# RTI0 register map
Vendor: Texas Instruments
Peripheral module from a debugger description file (folder am65x).
Registers are 32-bit, read-write, reset 0x0 unless marked. A register's access mark holds for its fields unless they carry their own. Offsets are as the file gives them; lines under a group give offsets from that group; [hi:lo] are bit positions; {n}, {i} and the like mark numbered series; 'fields as' and 'values as' point back to an identical list; <NAME> marks a mode.

## RTI0
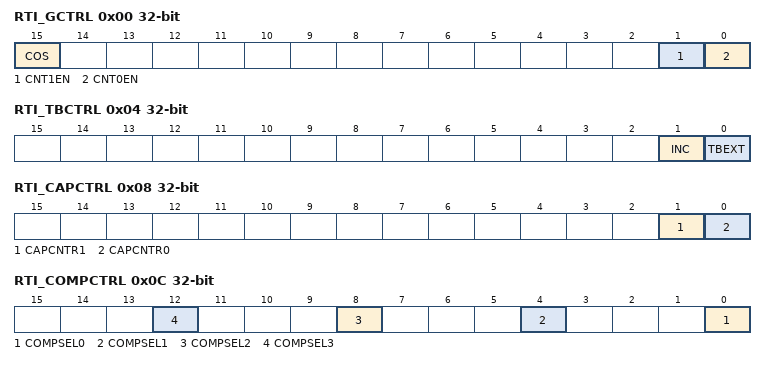
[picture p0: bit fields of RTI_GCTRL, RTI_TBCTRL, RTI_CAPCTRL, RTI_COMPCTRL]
0x00 RTI_GCTRL access per field
  [15] COS rw — Continue On Suspend. This bit determines if both counters are stopped when the device goes into debug mode or if they continue counting. User and privilege mode (read): 0 = counters are stopped while in debug mode 1 = counters are running while in debug mode Privilege mode (write): 0 = stop counters in debug mode 1 = continue counting in debug mode
  [1] CNT1EN rw — Counter 1 Enable. The CNT1EN bit starts and stops the operation of counter block1 (UC1 and FRC1). User and privilege mode (read): 0 = counters are stopped 1 = counters are running Privilege mode (write): 0 = stop counters 1 = start counters
  [0] CNT0EN rw — Counter 0 Enable. The CNT0EN bit starts and stops the operation of counter block0 (UC0 and FRC0). User and privilege mode (read): 0 = counters are stopped 1 = counters are running Privilege mode (write): 0 = stop counters 1 = start counters
0x04 RTI_TBCTRL access per field
  [1] INC rw — This bit determines whether the Free Running Counter 0 is automatically incremented if a failing clock on the NTUx signal is detected. User and privilege mode (read): 0 = FRC0 will not be incremented 1 = FRC0 will be incremented Privilege mode (write): 0 = Do not increment FRC0 on failing external clock 1 = Increment FRC0 on failing external clock
  [0] TBEXT rw — The Timebase External bit selects whether the Free Running Counter 0 is clocked by the internal Up Counter 0 or from the external signal NTUx. Since setting the TBEXT bit to 1 resets Up Counter 0, Free Running Counter 0 will not be incremented in this occurence. The only source which is able to increment Free Running Counter 0 is NTUx. When the Timebase Supervisor circuit detects a missing clockedge, then the TBEXT bit is reset. The selection if the external signal should be used, can only be done by software. User and privilege mode (read): 0 = UC0 clocks FRC0 1 = NTUx clocks FRC0 Privilege mode (write): 0 = MUX is switched to internal UC0 clocking scheme 1 = MUX is switched to external NTUx clocking scheme
0x08 RTI_CAPCTRL access per field
  [1] CAPCNTR1 rw — Capture Counter 0.
  [0] CAPCNTR0 rw — Capture Counter 0. This bit determines, which external interrupt source triggers a capture event of both UC0 and FRC0. User and privilege mode (read): 0 = capture event is triggered by Capture Event Source 0 1 = capture event is triggered by Capture Event Source 1 Privilege mode (write): 0 = enable capture event triggered by Capture Event Source 0 1 = enable capture event triggered by Capture Event Source 1
0x0C RTI_COMPCTRL access per field
  [4n] COMPSEL{n} rw (n=0..3) — Compare Select {n}. This bit determines the counter with which the compare value hold in compare register {n} is compared. User and privilege mode (read): 0 = value will be compared with FRC 0 1 = value will be compared with FRC 1 Privilege mode (write): 0 = enable compare with FRC 0 1 = enable compare with FRC 1
0x10 RTI_FRC0 — This registers holds the current value of the Free Running Counter 0 and will be updated continuously.
  [31:0] FRC0 — Free Running Counter 0. User and privilege mode (read): current value of the counter Privilege mode (write): The counter can be preset by writing to this register. The counter increments then from this written value upwards. Presetting counters, If counters have to be preset, they have to be stopped from counting in the
0x14 RTI_UC0
  [31:0] UC0 — Up Counter 0. User and privilege mode (read): value of the counter when the Free Running Counter 0 was read Privilege mode (write): the counter can be preset by writing to this register. The counter increments then from this written value upwards. Presetting counters: If counters have to be preset, they have to be stopped from counting in the
0x18 RTI_CPUC0
  [31:0] CPUC0 — Compare Up Counter 0. ARRAY(0x1f04380) ARRAY(0x1f04410) User and privilege mode (read): current compare value Privilege mode (write when TBEXT = 0): the compare value is updated Privilege mode (write when TBEXT = 1): the compare value is not changed
0x20 RTI_CAFRC0 ro
  [31:0] CAFRC0 — Capture Free Running Counter 0. User and privilege mode (read): value of Free Running Counter 0 on a capture event
0x24 RTI_CAUC0 ro
  [31:0] CAUC0 — Capture Up Counter 0. User and privilege mode (read): value of Up Counter 0 on a capture event
0x30 RTI_FRC1
  [31:0] FRC1 — Free Running Counter 1. User and privilege mode (read): current value of the counter Privilege mode (write): the counter can be preset by writing to this register. The counter increments then from this written value upwards. If counters have to be preset, they have to be stopped from counting in the
0x34 RTI_UC1
  [31:0] UC1 — Up Counter 1. User and privilege mode (read): value of the counter when the Free Running Counter 1 was read Privilege mode (write): the counter can be preset by writing to this register. The counter increments then from this written value upwards. Presetting counters: If counters have to be preset, they have to be disabled in the
0x38 RTI_CPUC1
  [31:0] CPUC1 — Compare Up Counter 1. ARRAY(0x1f1c750) ARRAY(0x1f1c7e0) User and privilege mode (read): current compare value Privilege mode (write): the compare value is updated
0x40 RTI_CAFRC1 ro
  [31:0] CAFRC1 — Capture Free Running Counter 1. User and privilege mode (read): value of Free Running Counter 1 on a capture event
0x44 RTI_CAUC1 ro
  [31:0] CAUC1 — Capture Up Counter 1. User and privilege mode (read): value of Up Counter 1 on a capture event
{0x50+8i} RTI_COMP{i} (i=0..3)
  [31:0] COMP{i} — Compare {i}. User and privilege mode (read): current compare value Privilege mode (write): update of the compare register with a new compare value Reset behavior: A reset does not generate a compare match, since the compare logic will only be active, when the associated counter block is enabled.
0x54 RTI_UDCP0
  [31:0] UDCP0 — Update Compare 0 Register. User and privilege mode (read): value to be added to the compare 0 register on the next compare match Privilege mode (write): new update value
0x5C RTI_UDCP1
  [31:0] UDCP1 — Update Compare 1 Register. User and privilege mode (read): value to be added to the compare 1 register on the next compare match Privilege mode (write): new update value
0x64 RTI_UDCP2 — This registers holds a value, which is added to the value in the compare 2 register each time a compare matches. This gives the possibility to generate periodic interrupts without software intervention.
  [31:0] UDCP2 — Update Compare 2 Register. User and privilege mode (read): value to be added to the compare 2 register on the next compare match Privilege mode (write): new update value
0x6C RTI_UDCP3
  [31:0] UDCP3 — Update Compare 3 Register. User and privilege mode (read): value to be added to the compare 3 register on the next compare match Privilege mode (write): new update value
0x70 RTI_TBLCOMP
  fields as RTI_UDCP3
0x74 RTI_TBHCOMP
  [31:0] TBHCOMP — This value determines when the edge detection circuit will stop monitoring the NTUx signal. It will be compared with Up Counter 0.
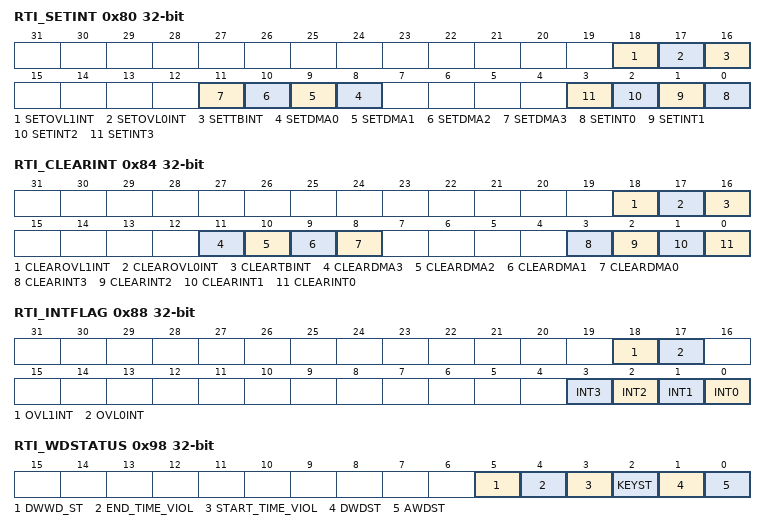
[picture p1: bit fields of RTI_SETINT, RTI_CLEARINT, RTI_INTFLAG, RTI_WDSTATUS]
0x80 RTI_SETINT access per field — This register prevents the necessity of a read-modify-write operation if a particular interrupt should be enabled. Some of the RTI features described in this section may not be supported on this family of devices. For more information, see , RTI Not Supported Features.
  [18] SETOVL1INT rw — Set Free Running Counter 1 Overflow Interrupt. User and privilege mode (read): 0 = interrupt is disabled 1 = interrupt is enabled Privilege mode (write): 0 = leaves the corresponding bit unchanged 1 = enable interrupt
  [17] SETOVL0INT rw — Set Free Running Counter 0 Overflow Interrupt. User and privilege mode (read): 0 = interrupt is disabled 1 = interrupt is enabled Privilege mode (write): 0 = leaves the corresponding bit unchanged 1 = enable interrupt
  [16] SETTBINT rw — User and privilege mode (read): 0 = interrupt is disabled 1 = interrupt is enabled Privilege mode (write): 0 = leaves the corresponding bit unchanged 1 = enable interrupt
  [n+8] SETDMA{n} rw (n=0..3) — Set Compare DMA Request {n}. User and privilege mode (read): 0 = DMA request is disabled 1 = DMA request is enabled Privilege mode (write): 0 = leaves the corresponding bit unchanged 1 = enable DMA request
  [n] SETINT{n} rw (n=0..3) — Set Compare Interrupt {n}. User and privilege mode (read): 0 = interrupt is disabled 1 = interrupt is enabled Privilege mode (write): 0 = leaves the corresponding bit unchanged 1 = enable interrupt
0x84 RTI_CLEARINT access per field — This register prevents the necessity of a read-modify-write operation if a particular interrupt should be disabled. Some of the RTI features described in this section may not be supported on this family of devices. For more information, see , RTI Not Supported Features.
  [18] CLEAROVL1INT rw — Clear Free Running Counter 1 Overflow Interrupt. User and privilege mode (read): 0 = interrupt is disabled 1 = interrupt is enabled Privilege mode (write): 0 = leaves the corresponding bit unchanged 1 = disable interrupt
  [17] CLEAROVL0INT rw — Clear Free Running Counter 0 Overflow Interrupt. User and privilege mode (read): 0 = interrupt is disabled 1 = interrupt is enabled Privilege mode (write): 0 = leaves the corresponding bit unchanged 1 = disable interrupt
  [16] CLEARTBINT rw — User and privilege mode (read): 0 = interrupt is disabled 1 = interrupt is enabled Privilege mode (write): 0 = leaves the corresponding bit unchanged 1 = disable interrupt
  [11] CLEARDMA3 rw — Clear Compare DMA Request 3. User and privilege mode (read): 0 = DMA request is disabled 1 = DMA request is enabled Privilege mode (write): 0 = leaves the corresponding bit unchanged 1 = disable DMA request
  [10] CLEARDMA2 rw — Clear Compare DMA Request 2. User and privilege mode (read): 0 = DMA request is disabled 1 = DMA request is enabled Privilege mode (write): 0 = leaves the corresponding bit unchanged 1 = disable DMA request
  [9] CLEARDMA1 rw — Clear Compare DMA Request 1. User and privilege mode (read): 0 = DMA request is disabled 1 = DMA request is enabled Privilege mode (write): 0 = leaves the corresponding bit unchanged 1 = disable DMA request
  [8] CLEARDMA0 rw — Clear Compare DMA Request 0.
  [3] CLEARINT3 rw — Clear Compare Interrupt 3. User and privilege mode (read): 0 = interrupt is disabled 1 = interrupt is enabled Privilege mode (write): 0 = leaves the corresponding bit unchanged 1 = disable interrupt
  [2] CLEARINT2 rw — Clear Compare Interrupt 2. User and privilege mode (read): 0 = interrupt is disabled 1 = interrupt is enabled Privilege mode (write): 0 = leaves the corresponding bit unchanged 1 = disable interrupt
  [1] CLEARINT1 rw — Clear Compare Interrupt 1.
  [0] CLEARINT0 rw — Clear Compare Interrupt 0. User and privilege mode (read): 0 = interrupt is disabled 1 = interrupt is enabled Privilege mode (write): 0 = leaves the corresponding bit unchanged 1 = disable interrupt
0x88 RTI_INTFLAG ro — The corresponding flags are set at every compare match of Free Running Counterx and RTICOMPx value, regardless if the interrupt is enabled or not.
  [18] OVL1INT — Free Running Counter 1 Overflow Interrupt Flag. User and privilege mode (read): determines if an interrupt is pending 0 = no interrupt pending 1 = interrupt pending Privilege mode (write): 0 = leaves the bit unchanged 1 = set the bit to 0
  [17] OVL0INT — Free Running Counter 0 Overflow Interrupt Flag. User and privilege mode (read): determines if an interrupt is pending 0 = no interrupt pending 1 = interrupt pending Privilege mode (write): 0 = leaves the bit unchanged 1 = set the bit to 0
  [n] INT{n} (n=0..3) — Interrupt Flag {n}. User and privilege mode (read): determines if an interrupt is pending 0 = no interrupt pending 1 = interrupt pending Privilege mode (write): 0 = leaves the bit unchanged 1 = set the bit to 0
0x90 RTI_DWDCTRL reset 0x5312ACED — Some of the RTI features described in this section may not be supported on this family of devices. For more information, see , RTI Not Supported Features. This register's functionality is dependent on whether the DWD is implemented to be always enabled or not. If the DWD is always enabled, then the DWD is automatically enabled after system reset is released and cannot be disabled by software. In that case, this register is redundant and any writes to this register have no effect on the DWD functionality. If, however, the DWD is not enabled upon release of system reset, then the software has to write to the DWDCTRL field in order to enable the DWD, as described below. Once enabled, the watchdog can only be disabled by a system reset. The application cannot disable the watchdog. The register also implements a one-time-write constraint. That is, once the application writes to this register to enable the watchdog, all further writes are ignored.
  [31:0] DWDCTRL — Digital Watchdog Control. User and privilege mode (read): 5312ACEDh = DWD counter is disabled. This is the default value. A98559DAh = DWD counter is enabled Any other value = DWD counter state is unchanged (enabled or disabled) Privilege mode (write): A98559DAh = DWD counter is enabled Any other value = State of DWD counter is unchanged (stays enabled or disabled) One-Write Functionality of DWDCTRL Register: The
0x94 RTI_DWDPRLD access per field reset 0xFFF — Some of the RTI features described in this section may not be supported on this family of devices. For more information, see , RTI Not Supported Features.
  [11:0] DWDPRLD rw — Digital Watchdog Preload Value. User and privilege mode (read): A read from this register in any CPU mode returns the current preload value. Privilege mode (write): If the DWD is always enabled after reset is released: The DWD starts counting down from the reset value of the counter, that is, 0x002DFFFF. The application can configure the DWD preload register any time before this down counter expires. When the application services the DWD, the preload register contents are copied left-justified into the DWD down counter and it starts counting down from that value. If the DWD is implemented such that the down counter is enabled by software: The DWD preload register can be configured only when the DWD is disabled. Therefore, the application can only configure the DWD preload register before it enables the DWD down counter. The expiration time of the DWD Down Counter can be determined with following equation: ARRAY(0x1F75D70) where:
0x98 RTI_WDSTATUS ro — Some of the RTI features described in this section may not be supported on this family of devices. For more information, see , RTI Not Supported Features. The values of the following status bits will not be affected by a system reset. These bits are cleared by a power up reset, or by the application.
  [5] DWWD_ST — Windowed Watchdog Status. This bit denotes whether the time-window defined by the windowed watchdog configuration has been violated, or if a wrong key or key sequence was written to service the watchdog. User and privilege mode (read): 0 = no time-window violation has occurred. 1 = a time-window violation has occurred. The watchdog will generate either a system reset or a non-maskable interrupt to the CPU in this case. Privilege mode (write): 0 = leaves the current value unchanged. 1 = clears the bit to 0. This will also clear all other status flags in the
  [4] END_TIME_VIOL — Windowed Watchdog End Time Violation Status. This bit denotes whether the end-time defined by the windowed watchdog configuration has been violated. This bit is effectively a copy of the DWD ST status flag. User and priviledge mode (read): 0 = no end-time window violation has occurred. 1 = the end-time defined by the windowed watchdog configuration has been violated. Priviledge mode (write): 0 = leaves the current value unchanged. 1 = clears the bit to 0.
  [3] START_TIME_VIOL — Windowed Watchdog End Time Violation Status. This bit denotes whether the start-time defined by the windowed watchdog configuration has been violated. This indicates that the WWD was serviced before the service window was opened. User and priviledge mode (read): 0 = no start-time window violation has occurred. 1 = the start-time defined by the windowed watchdog configuration has been violated. Priviledge mode (write): 0 = leaves the current value unchanged. 1 = clears the bit to 0.
  [2] KEYST — Watchdog KeyStatus.
  [1] DWDST — Digital Watchdog Status.
  [0] AWDST — Analog Watchdog Status.
0x9C RTI_WDKEY access per field reset 0xA35C — Some of the RTI features described in this section may not be supported on this family of devices. For more information, see , RTI Not Supported Features.
  [15:0] WDKEY rw — Watchdog Key. User and privilege mode reads are indeterminate. Privilege mode (write): A write of 0xE51A followed by 0xA35C in two separate write operations defines the Key Sequence and discharges the watchdog capacitor. This also causes the upper 12 bits of the DWD down counter to be reloaded with the contents of the DWD preload register and the lower 13 bits to become all 1 s. Writing any other value causes a digital watchdog reset. Register write access time precaution: The user has to take into account that the write to the register takes 3 RTI_ICLK cycle. This needs to be considered for the AWD/DWD expiration calculation. Step 1:
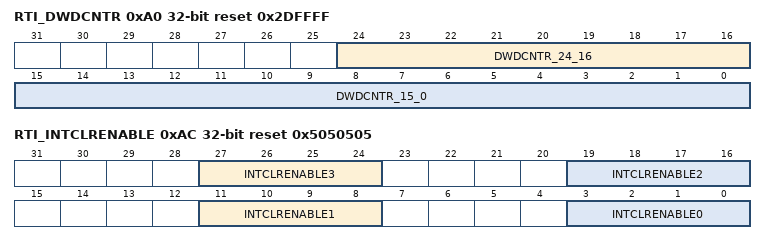
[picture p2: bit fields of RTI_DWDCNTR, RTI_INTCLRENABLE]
0xA0 RTI_DWDCNTR ro reset 0x2DFFFF — Some of the RTI features described in this section may not be supported on this family of devices. For more information, see , RTI Not Supported Features.
  [24:16] DWDCNTR_24_16 — Digital Watchdog Down Counter. The value of the DWDCNTR after a system reset is 0x002DFFFF. When the DWD is enabled and the DWD counter starts counting down from this value with an RTI_FCLK time base of 3MHz, a watchdog reset will be generated in 1 second. User and privilege mode (read): Reads return the current counter value. Privilege mode (write): Writes don t have an effect.
  [15:0] DWDCNTR_15_0 — Digital Watchdog Down Counter. The value of the DWDCNTR after a system reset is 0x002DFFFF. When the DWD is enabled and the DWD counter starts counting down from this value with an RTI_FCLK time base of 3MHz, a watchdog reset will be generated in 1 second. User and privilege mode (read): Reads return the current counter value. Privilege mode (write): Writes don t have an effect.
0xA4 RTI_WWDRXNCTRL access per field reset 0x5
  [3:0] WWDRXN rw — Digital Windowed Watchdog Reaction. User and privilege mode (read), privileged mode (write): 0x5 = This is the default value. The windowed watchdog will cause a reset if the watchdog is serviced outside the time window defined by the configuration, or if the watchdog is not serviced at all. 0xA = The windowed watchdog will generate a non-maskable interrupt to the CPU if the watchdog is serviced outside the time window defined by the configuration, or if the watchdog is not serviced at all. Writing any other value will cause a system reset if the watchdog is serviced outside the time window defined by the configuration, or if the watchdog is not serviced at all. Configuration of DWWD Reaction: The DWWD reaction can be selected by the application even when the DWWD counter is already enabled. If a change to the WWDRXN is made before the watchdog service window is opened, then the change in the configuration takes effect immediately. If a change to the WWDRXN is made when the watchdog service window is already open, then the change in configuration takes effect only after the watchdog is serviced.
0xA8 RTI_WWDSIZECTRL 16-bit reset 0x5
  [15:0] WWDSIZE — Same as below. Digital Windowed Watchdog Window Size. User and privilege mode (read), privileged mode (write): Value written to WWDSIZE: 0x00000005 = 100% Window Size (The functionality is the same as the standard time-out digital watchdog.) Value written to WWDSIZE: 0x00000050 = 50% Window Size Value written to WWDSIZE: 0x00000500 = 25% Window Size Value written to WWDSIZE: 0x00005000 = 12.5% Window Size Value written to WWDSIZE: 0x00050000 = 6.25% Window Size Value written to WWDSIZE: 0x00500000 = 3.125% Window Size Value written to WWDSIZE: Any other value = 3.125% Window Size Incorrect value being written to watchdog window size control register: If an incorrect value is written to the WWDSIZE field, or if a system disturbance causes the WWDSIZE field to have a value other than 0x5, 0x50, 0x500, 0x5000, 0x50000, or 0x500000, then the window size will be configured to be 3.125%. This increases the chances of getting a reset due to the windowed watchdog, which enables the system to handle the cause for the incorrect configuration. Configuration of DWWD Window Size: The DWWD window size can be selected by the application even when the DWWD counter is already enabled. If a change to the WWDSIZE is made before the watchdog service window is opened, then the change in the configuration takes effect immediately. If a change to the WWDSIZE is made when the watchdog service window is already open, then the change in configuration takes effect only after the watchdog is serviced.
0xAC RTI_INTCLRENABLE access per field reset 0x5050505
  [27:24] INTCLRENABLE3 rw — Enables the auto-clear functionality on the compare 3 interrupt. User and Privileged mode (read): 0x5 = Auto-clear for compare 3 interrupt is disabled. Any other value = Auto-clear for compare 3 interrupt is enabled. Privileged mode (write): 0x5 = Disables the auto-clear functionality on the compare 3 interrupt. Any other value = Enables the auto-clear functionality on the compare 3 interrupt.
  [19:16] INTCLRENABLE2 rw — Enables the auto-clear functionality on the compare 2 interrupt. User and Privileged mode (read): 0x5 = Auto-clear for compare 2 interrupt is disabled. Any other value = Auto-clear for compare 2 interrupt is enabled. Privileged mode (write): 0x5 = Disables the auto-clear functionality on the compare 2 interrupt. Any other value = Enables the auto-clear functionality on the compare 2 interrupt.
  [11:8] INTCLRENABLE1 rw — Enables the auto-clear functionality on the compare 1 interrupt. User and Privileged mode (read): 0x5 = Auto-clear for compare 1 interrupt is disabled. Any other value = Auto-clear for compare 1 interrupt is enabled. Privileged mode (write): 0x5 = Disables the auto-clear functionality on the compare 1 interrupt. Any other value = Enables the auto-clear functionality on the compare 1 interrupt.
  [3:0] INTCLRENABLE0 rw — Enables the auto-clear functionality on the compare 0 interrupt. User and Privileged mode (read): 0x5 = Auto-clear for compare 0 interrupt is disabled. Any other value = Auto-clear for compare 0 interrupt is enabled. Privileged mode (write): 0x5 = Disables the auto-clear functionality on the compare 0 interrupt. Any other value = Enables the auto-clear functionality on the compare 0 interrupt. Hook-up of Compare Interrupt to a device pin: The RTI module generates up to 4 compare interrupts. The connection between one or more of these compare interrupt(s) to a device pin is completely device-dependent. Refer to the device datasheet to identify the actual pin(s) that connects to the compare interrupt(s).
{0xB0+4i} RTI_COMP{i}CLR (i=0..3)
  [31:0] COMP{i}CLR — Compare {i} Clear. User and privilege mode (read): current compare value Privilege mode (write): update of the compare register with a new compare value Reset behavior: A reset does not generate a compare match, since the compare logic will only be active, when the associated counter block is enabled.
